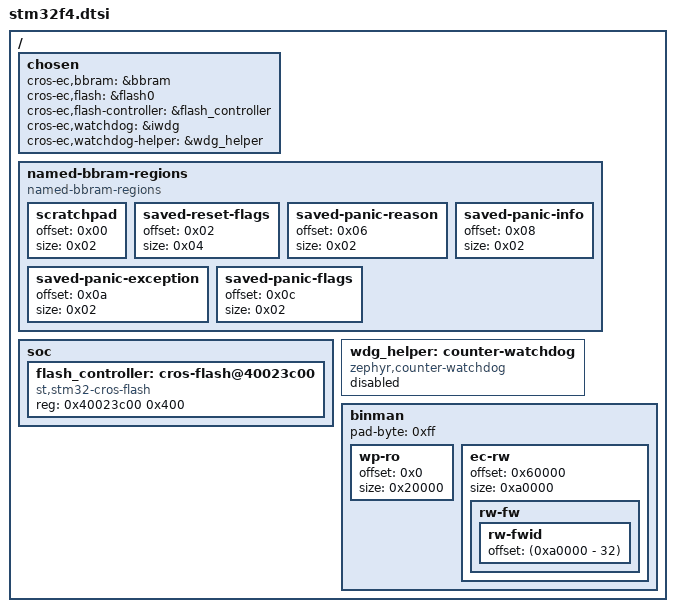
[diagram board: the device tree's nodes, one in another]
/* Copyright 2022 The ChromiumOS Authors.
 * Use of this source code is governed by a BSD-style license that can be
 * found in the LICENSE file.
 */

#include <cros/binman.dtsi>

/ {
        chosen {
		cros-ec,bbram = &bbram;
		//cros-ec,espi = &espi0;
		cros-ec,flash = &flash0;
		cros-ec,flash-controller = &flash_controller;
		cros-ec,watchdog = &iwdg;
		cros-ec,watchdog-helper = &wdg_helper;
        };

        named-bbram-regions {
                compatible = "named-bbram-regions";

                scratchpad {
                        offset = <0x00>;
                        size = <0x02>;
                };
                saved-reset-flags {
                        offset = <0x02>;
                        size = <0x04>;
                };
		saved-panic-reason {
                        offset = <0x06>;
                        size = <0x02>;
		};
		saved-panic-info {
                        offset = <0x08>;
                        size = <0x02>;
		};
		saved-panic-exception {
                        offset = <0x0a>;
                        size = <0x02>;
		};
		saved-panic-flags {
                        offset = <0x0c>;
                        size = <0x02>;
		};
        };

	soc {
		flash_controller: cros-flash@40023c00 {
			compatible = "st,stm32-cros-flash";
			reg = <0x40023c00 0x400>;
		};
	};

	wdg_helper: counter-watchdog {
		compatible = "zephyr,counter-watchdog";
		status = "disable";
	};

	binman {
		/* First 5 sectors (4 x 16KB, 1 x 64KB) used for RO */
		wp-ro {
			offset = <0x0>;
			size = <0x20000>;
		};

		/* Two sectors used for rollback (128KB each) */

		/* Remaining 5 sectors (128KB each) used for RW */
		ec-rw {
			offset = <0x60000>;
			size = <0xa0000>;
			rw-fw {
				rw-fwid {
					/* Fix the location of the FWID to the
					 * last 32 bytes of the flash. This
					 * ensures the RW entries in the FMAP
					 * stored in the RO section of flash
					 * are always correct.
					 */
					offset = <(0xa0000 - 32)>;
				};
			};
		};
		pad-byte = <0xff>;
	};
};
